# RK3399-AP register map
File version: 1
CPU: CA7 r0p1, little endian, MPU, FPU, I-cache, D-cache, VTOR, 4 interrupt priority bits, 0 interrupts
Registers are 32-bit, read-write, reset 0x0 unless marked. A register's access mark holds for its fields unless they carry their own. Offsets are from the block's base; [hi:lo] are bit positions; {n}, {i} and the like mark numbered series; 'fields as' and 'values as' point back to an identical list.

## GRF (part 1 of 4)
Base 0xFF770000
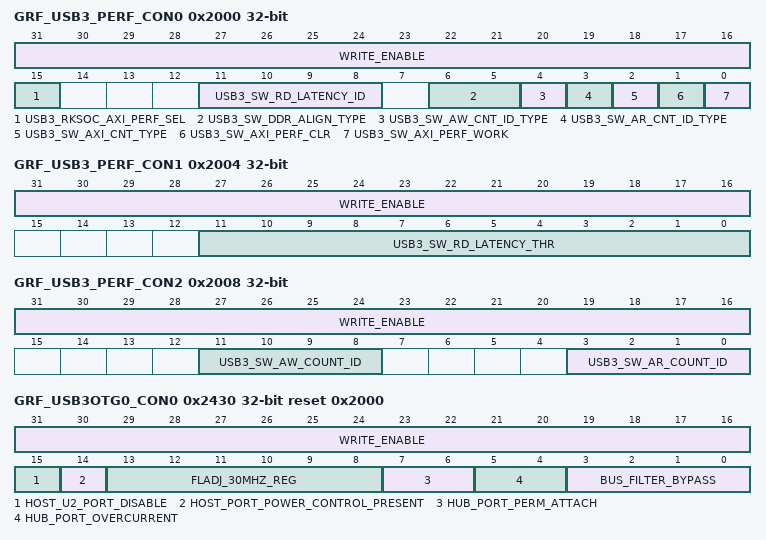
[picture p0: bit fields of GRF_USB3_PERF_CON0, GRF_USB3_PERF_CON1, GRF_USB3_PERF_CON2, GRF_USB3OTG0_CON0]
0x2000 GRF_USB3_PERF_CON0 — usb3 performance monitor control register
  [31:16] WRITE_ENABLE — bit0~15 write enable When bit 16=1, bit 0 can be written by software . When bit 16=0, bit 0 cannot be written by software; When bit 17=1, bit 1 can be written by software . When bit 17=0, bit 1 cannot be written by software; ...... When bit 31=1, bit 15 can be written by software . When bit 31=0, bit 15 cannot be written by software;
  [15] USB3_RKSOC_AXI_PERF_SEL — 0: usb3otg0 1: usb3otg1
  [11:8] USB3_SW_RD_LATENCY_ID — Axi read channel id for latency AXI_PERFormance test
  [6:5] USB3_SW_DDR_ALIGN_TYPE — 0: 16-Byte align 1: 32-Byte align 2: 64-Byte align 3: 128-Byte align
  [4] USB3_SW_AW_CNT_ID_TYPE — axi_perf counter id control 0: count all read channel id 1: count sw_ar_count_id read channel only
  [3] USB3_SW_AR_CNT_ID_TYPE — axi_perf counter id control 0: count all read channel id 1: count sw_ar_count_id read channel only
  [2] USB3_SW_AXI_CNT_TYPE — axi_perf counter type 0: axi transfer test 1: ddr align transfer test
  [1] USB3_SW_AXI_PERF_CLR — Fi axi_perf clear bit 0: disable 1: enable
  [0] USB3_SW_AXI_PERF_WORK — axi_perf enable bit 0: disable 1: enable
0x2004 GRF_USB3_PERF_CON1 — usb3 performance monitor control register
  [31:16] WRITE_ENABLE — bit0~15 write enable When bit 16=1, bit 0 can be written by software . When bit 16=0, bit 0 cannot be written by software; When bit 17=1, bit 1 can be written by software . When bit 17=0, bit 1 cannot be written by software; ...... When bit 31=1, bit 15 can be written by software . When bit 31=0, bit 15 cannot be written by software;
  [11:0] USB3_SW_RD_LATENCY_THR — Axi read channel id for latency AXI_PERFormance test
0x2008 GRF_USB3_PERF_CON2 — usb3 performance monitor control register
  [31:16] WRITE_ENABLE — bit0~15 write enable When bit 16=1, bit 0 can be written by software . When bit 16=0, bit 0 cannot be written by software; When bit 17=1, bit 1 can be written by software . When bit 17=0, bit 1 cannot be written by software; ...... When bit 31=1, bit 15 can be written by software . When bit 31=0, bit 15 cannot be written by software;
  [11:8] USB3_SW_AW_COUNT_ID — When sw_aw_cnt_id_type=1, only count the id designated by sw_aw_count_id
  [3:0] USB3_SW_AR_COUNT_ID — When sw_ar_cnt_id_type=1, only count the id designated by sw_ar_count_id
0x200C GRF_USB3_PERF_RD_MAX_LATENCY_NUM — usb3 performance monitor status register
  [15:0] RD_MAX_LATENCY_R — axi read max latency oaxi read max latency outpututput
0x2010 GRF_USB3_PERF_RD_LATENCY_SAMP_NUM — usb3 performance monitor status register
  [31:0] RD_LATENCY_SAMP_R — AXI read latency total sample number
0x2014 GRF_USB3_PERF_RD_LATENCY_ACC_NUM — usb3 performance monitor status register
  [31:0] RD_LATENCY_ACC_CNT_R — AXI read latency (>sw_rd_latency_thr) total number
0x2018 GRF_USB3_PERF_RD_AXI_TOTAL_BYTE — usb3 performance monitor status register
  [31:0] RD_AXI_TOTAL_BYTE — AXI active total read bytes/ddr align read bytes
0x201C GRF_USB3_PERF_WR_AXI_TOTAL_BYTE — usb3 performance monitor status register
  [31:0] WR_AXI_TOTAL_BYTE — AXI active total write bytes/ddr align write bytes
0x2020 GRF_USB3_PERF_WORKING_CNT — usb3 performance monitor status register
  [31:0] WORKING_CNT_R — working counter
0x2430 GRF_USB3OTG0_CON0 reset 0x2000 — USB3 OTG0 GRF Register0
  [31:16] WRITE_ENABLE — bit0~15 write enable When bit 16=1, bit 0 can be written by software . When bit 16=0, bit 0 cannot be written by software; When bit 17=1, bit 1 can be written by software . When bit 17=0, bit 1 cannot be written by software; ...... When bit 31=1, bit 15 can be written by software . When bit 31=0, bit 15 cannot be written by software;
  [15] HOST_U2_PORT_DISABLE — host_u2_port_disable USB2.0 Port Disable control. 0: Port Enabled 1: Port Disabled When 1, this signal stops reporting connect/disconnect events the port and keeps the port in disabled state.
  [14] HOST_PORT_POWER_CONTROL_PRESENT — host_port_power_control_present This indicates whether the host controller implementation includes port power control. 0: Indicates that the port does not have port power switches. 1: Indicates that the port has port power switches
  [13:8] FLADJ_30MHZ_REG — fladj_30mhz_reg HS Jitter Adjustment. Indicates the correction required to accommodate mac3 clock and utmi clock jitter to measure 125 \'s duration. With fladj_30mhz_reg tied to zero, the high speed 125us micro-frame is counted for 123933ns. You must program the value in terms of high speed bit times in a 30 MHz cycle. The default value that must be driven is 32 (assuming 30 MHz perfect clock).
  [7:6] HUB_PORT_PERM_ATTACH — hub_port_perm_attach Indicates if the device attached to a downstream port is permanently attached or not. 0: Not permanently attached 1: Permanently attached Bit0 is for USB2.0 port and bit1 are for USB 3.0 SS port.
  [5:4] HUB_PORT_OVERCURRENT — hub_port_overcurrent This is the per port Overcurrent indication of the root-hub ports: 0: No Overcurrent 1: Overcurrent Bit0 is for USB 2.0 port and bit1 are for USB 3.0 SS port.
  [3:0] BUS_FILTER_BYPASS — bus_filter_bypass It is expected that this signal is set or reset at power-on reset and is not changed during the normal operation of the core. The function of each bit is: bus_filter_bypass[3]: Bypass the filter for utmiotg_iddig bus_filter_bypass[2]: Bypass the filters for utmisrp_bvalid and utmisrp_sessend bus_filter_bypass[1]: Bypass the filter for pipe3_PowerPresent all U3 ports bus_filter_bypass[0]: Bypass the filter for utmiotg_vbusvalid all U2 ports In non-OTG Host-only mode, internal bus filters are not needed. Values: 1\'b0: Bus filter(s) enabled 1\'b1: Bus filter(s) disabled (bypassed)
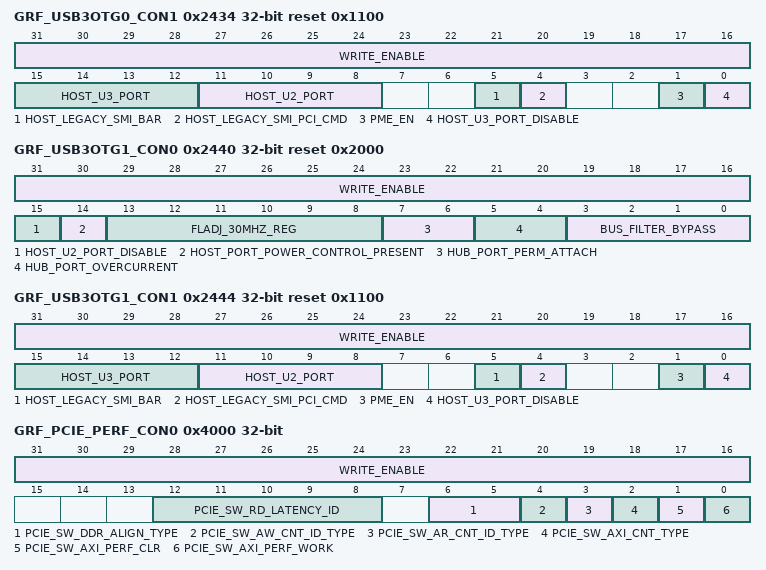
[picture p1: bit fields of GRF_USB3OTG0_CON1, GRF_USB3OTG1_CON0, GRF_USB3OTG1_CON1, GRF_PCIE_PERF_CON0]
0x2434 GRF_USB3OTG0_CON1 reset 0x1100 — USB3 OTG0 GRF Register1
  [31:16] WRITE_ENABLE — bit0~15 write enable When bit 16=1, bit 0 can be written by software . When bit 16=0, bit 0 cannot be written by software; When bit 17=1, bit 1 can be written by software . When bit 17=0, bit 1 cannot be written by software; ...... When bit 31=1, bit 15 can be written by software . When bit 31=0, bit 15 cannot be written by software;
  [15:12] HOST_U3_PORT — host_u3_port xHCI usb3 port number, default as 1.
  [11:8] HOST_U2_PORT — host_u2_port xHCI host USB2 Port number, default as 1.
  [5] HOST_LEGACY_SMI_BAR — host_legacy_smi_bar Use this register to support SMI on BAR defined in xHCI spec. SW must set this register, then clear this register to indicate Base Address Register written
  [4] HOST_LEGACY_SMI_PCI_CMD — host_legacy_smi_pci_cmd Use this register to support SMI on PCI Command defined in xHCI spec. SW must set this register, then clear this register to indicate PCI command register written.
  [1] PME_EN — pme_en Enable signal for the pme_generation. Enable the core to assert pme_generation.
  [0] HOST_U3_PORT_DISABLE — host_u3_port_disable USB 3.0 SS Port Disable control. 0: Port Enabled 1: Port Disabled
0x2440 GRF_USB3OTG1_CON0 reset 0x2000 — USB3 OTG1 GRF Register0
  fields as GRF_USB3OTG0_CON0
0x2444 GRF_USB3OTG1_CON1 reset 0x1100 — USB3 OTG1 GRF Register1
  [31:16] WRITE_ENABLE — bit0~15 write enable When bit 16=1, bit 0 can be written by software . When bit 16=0, bit 0 cannot be written by software; When bit 17=1, bit 1 can be written by software . When bit 17=0, bit 1 cannot be written by software; ...... When bit 31=1, bit 15 can be written by software . When bit 31=0, bit 15 cannot be written by software;
  [15:12] HOST_U3_PORT — host_u3_port xHCI usb3 port number, default as 1.
  [11:8] HOST_U2_PORT — host_u2_port xHCI host USB2 port number, default as 1.
  [5] HOST_LEGACY_SMI_BAR — host_legacy_smi_bar Use this register to support SMI on BAR defined in xHCI spec. SW must set this register, then clear this register to indicate Base Address Register written
  [4] HOST_LEGACY_SMI_PCI_CMD — host_legacy_smi_pci_cmd Use this register to support SMI on PCI Command defined in xHCI spec. SW must set this register, then clear this register to indicate PCI command register written.
  [1] PME_EN — pme_en Enable signal for the pme_generation. Enable the core to assert pme_generation.
  [0] HOST_U3_PORT_DISABLE — host_u3_port_disable USB 3.0 SS Port Disable control. 0: Port Enabled 1: Port Disabled
0x2450 GRF_USB3OTG0_STATUS_LAT0 — USB3 OTG0 status register
  [31:0] USBCPHY0_OTG_UTMI_IDDIG — status of usbcphy0_otg_utmi_iddig[31:0]
0x2454 GRF_USB3OTG0_STATUS_LAT1 — USB3 OTG1 status register
  [31:0] USBCPHY0_OTG_UTMI_IDDIG — status of usbcphy0_otg_utmi_iddig[63:32]
0x2458 GRF_USB3OTG0_STATUS_CB — USB3 OTG0 status register
  [11:0] USB3OTG0_HOST_CURRENT_BELT — status of usb3otg0_host_current_belt
0x2460 GRF_USB3OTG1_STATUS_LAT0 — USB3 OTG1 status register
  [31:0] USBCPHY1_OTG_UTMI_IDDIG — status of usbcphy1_otg_utmi_iddig[31:0]
0x2464 GRF_USB3OTG1_STATUS_LAT1 — USB3 OTG1 status register
  [31:0] USBCPHY1_OTG_UTMI_IDDIG — status of usbcphy1_otg_utmi_iddig[63:32]
0x2468 GRF_USB3OTG1_STATUS_CB — USB3 OTG1 status register
  [11:0] USB3OTG1_HOST_CURRENT_BELT — status of usb3otg1_host_current_belt
0x4000 GRF_PCIE_PERF_CON0 — pcie performance monitor control register
  [31:16] WRITE_ENABLE — bit0~15 write enable When bit 16=1, bit 0 can be written by software . When bit 16=0, bit 0 cannot be written by software; When bit 17=1, bit 1 can be written by software . When bit 17=0, bit 1 cannot be written by software; ...... When bit 31=1, bit 15 can be written by software . When bit 31=0, bit 15 cannot be written by software;
  [12:8] PCIE_SW_RD_LATENCY_ID — Axi read channel id for latency AXI_PERFormance test
  [6:5] PCIE_SW_DDR_ALIGN_TYPE — 0: 16-Byte align 1: 32-Byte align 2: 64-Byte align 3: 128-Byte align
  [4] PCIE_SW_AW_CNT_ID_TYPE — 0: count all write channels 1: count sw_aw_count_id write channel only
  [3] PCIE_SW_AR_CNT_ID_TYPE — axi_perf counter id control 0: count all read channel id 1: count sw_ar_count_id read channel only
  [2] PCIE_SW_AXI_CNT_TYPE — axi_perf counter type 0: axi transfer test 1: ddr align transfer test
  [1] PCIE_SW_AXI_PERF_CLR — axi_perf clear bit 0: disable 1: enable
  [0] PCIE_SW_AXI_PERF_WORK — axi_perf enable bit 0: disable 1: enable
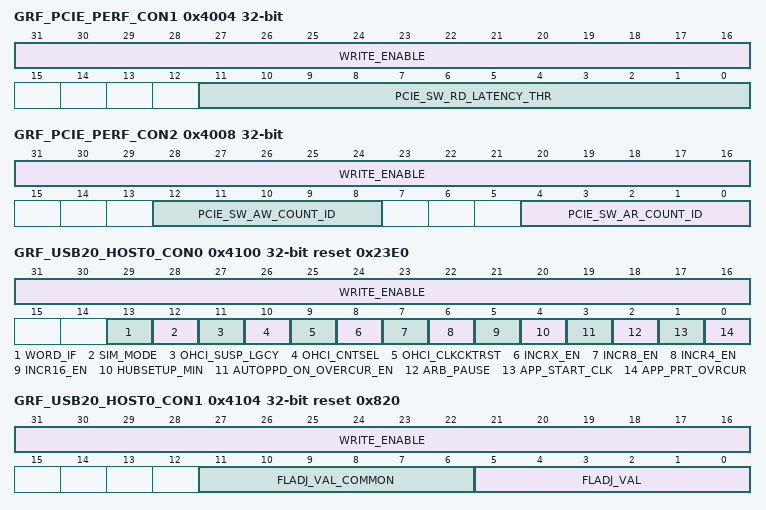
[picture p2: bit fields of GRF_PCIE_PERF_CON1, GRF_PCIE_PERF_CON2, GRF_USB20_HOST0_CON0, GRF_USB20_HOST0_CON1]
0x4004 GRF_PCIE_PERF_CON1 — pcie performance monitor control register
  [31:16] WRITE_ENABLE — bit0~15 write enable When bit 16=1, bit 0 can be written by software . When bit 16=0, bit 0 cannot be written by software; When bit 17=1, bit 1 can be written by software . When bit 17=0, bit 1 cannot be written by software; ...... When bit 31=1, bit 15 can be written by software . When bit 31=0, bit 15 cannot be written by software;
  [11:0] PCIE_SW_RD_LATENCY_THR — Axi read channel id for latency AXI_PERFormance test
0x4008 GRF_PCIE_PERF_CON2 — pcie performance monitor control register
  [31:16] WRITE_ENABLE — bit0~15 write enable When bit 16=1, bit 0 can be written by software . When bit 16=0, bit 0 cannot be written by software; When bit 17=1, bit 1 can be written by software . When bit 17=0, bit 1 cannot be written by software; ...... When bit 31=1, bit 15 can be written by software . When bit 31=0, bit 15 cannot be written by software;
  [12:8] PCIE_SW_AW_COUNT_ID — When sw_aw_cnt_id_type=1, only count the id designated by sw_aw_count_id
  [4:0] PCIE_SW_AR_COUNT_ID — When sw_ar_cnt_id_type=1, only count the id designated by sw_ar_count_id
0x400C GRF_PCIE_PERF_RD_MAX_LATENCY_NUM — pcieperformance monitor status register
  [12:0] RD_MAX_LATENCY_R — axi read max latency output
0x4010 GRF_PCIE_PERF_RD_LATENCY_SAMP_NUM — pcie performance monitor status register
  [26:0] RD_LATENCY_SAMP_R — AXI read latency total sample number
0x4014 GRF_PCIE_PERF_RD_LATENCY_ACC_NUM — pcie performance monitor status register
  fields as GRF_USB3_PERF_RD_LATENCY_ACC_NUM
0x4018 GRF_PCIE_PERF_RD_AXI_TOTAL_BYTE — pcie performance monitor status register
  fields as GRF_USB3_PERF_RD_AXI_TOTAL_BYTE
0x401C GRF_PCIE_PERF_WR_AXI_TOTAL_BYTE — pcie performance monitor status register
  fields as GRF_USB3_PERF_WR_AXI_TOTAL_BYTE
0x4020 GRF_PCIE_PERF_WORKING_CNT — pcie performance monitor status register
  [31:0] WORKING_CNT_R — working counter
0x4100 GRF_USB20_HOST0_CON0 reset 0x23E0 — USB20 Host0 GRF register0
  [31:16] WRITE_ENABLE — bit0~15 write enable When bit 16=1, bit 0 can be written by software . When bit 16=0, bit 0 cannot be written by software; When bit 17=1, bit 1 can be written by software . When bit 17=0, bit 1 cannot be written by software; ...... When bit 31=1, bit 15 can be written by software . When bit 31=0, bit 15 cannot be written by software;
  [13] WORD_IF — word_if 1: select 16bit utmi interface 0: select 8bit utmi interface Note: usb2phy only support 16bit interface.
  [12] SIM_MODE — sim_mode Simulation only.
  [11] OHCI_SUSP_LGCY
  [10] OHCI_CNTSEL
  [9] OHCI_CLKCKTRST
  [8] INCRX_EN — incrx_en Forces AHB master to start INCR4/8/16 busts only on burst boundaries. AHB requires that double word width burst be addressed-aligned only to the double-word boundary. 1\'b1: Start INCRX burst only on burst x-aligned addresses 1\'b0: Normal AHB operation; start bursts on any double word boundary Note: When this function is enabled, the burst are started only when the lowest bits of haddr are: INCR4: haddr[3:0] == 4\'b0000 INCR8: haddr[4:0] == 5\'b00000 INCR16: haddr[5:0] == 6\'b000000
  [7] INCR8_EN — incr8_en 1: enable AHB INCR8 burst 0: disable AHB INCR8 burst
  [6] INCR4_EN — incr4_en 1: enable AHB INCR4 burst 0: disable AHB INCR4 burst
  [5] INCR16_EN — incr16_en 1: enable AHB INCR16 burst 0: disable AHB INCR16 burst
  [4] HUBSETUP_MIN
  [3] AUTOPPD_ON_OVERCUR_EN
  [2] ARB_PAUSE
  [1] APP_START_CLK
  [0] APP_PRT_OVRCUR
0x4104 GRF_USB20_HOST0_CON1 reset 0x820 — USB20 Host0 GRF register1
  [31:16] WRITE_ENABLE — bit0~15 write enable When bit 16=1, bit 0 can be written by software . When bit 16=0, bit 0 cannot be written by software; When bit 17=1, bit 1 can be written by software . When bit 17=0, bit 1 cannot be written by software; ...... When bit 31=1, bit 15 can be written by software . When bit 31=0, bit 15 cannot be written by software;
  [11:6] FLADJ_VAL_COMMON — fladj_val_common Must set this register to 0x20.
  [5:0] FLADJ_VAL — fladj_val Must set this register to 0x20.
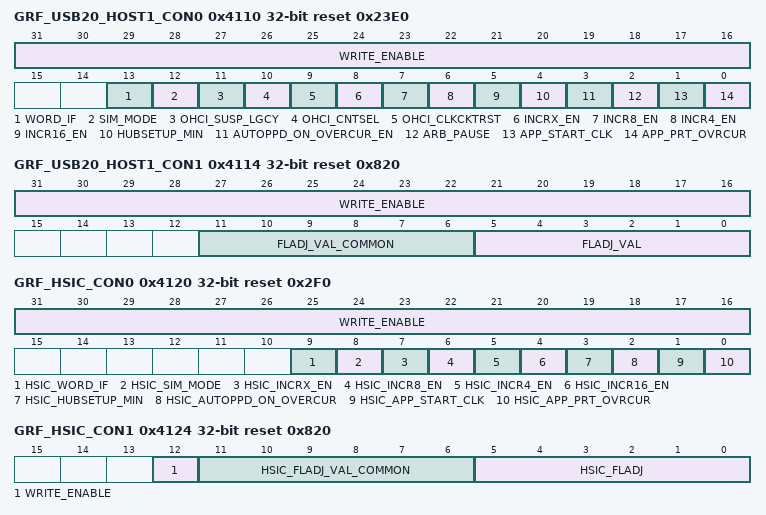
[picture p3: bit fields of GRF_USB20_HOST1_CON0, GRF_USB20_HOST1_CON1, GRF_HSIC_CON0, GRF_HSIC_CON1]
0x4110 GRF_USB20_HOST1_CON0 reset 0x23E0 — USB20 Host1 GRF register0
  fields as GRF_USB20_HOST0_CON0
0x4114 GRF_USB20_HOST1_CON1 reset 0x820 — USB20 Host1 GRF register1
  fields as GRF_USB20_HOST0_CON1
0x4120 GRF_HSIC_CON0 reset 0x2F0 — HSIC controller GRF register 0
  [31:16] WRITE_ENABLE — bit0~15 write enable When bit 16=1, bit 0 can be written by software . When bit 16=0, bit 0 cannot be written by software; When bit 17=1, bit 1 can be written by software . When bit 17=0, bit 1 cannot be written by software; ...... When bit 31=1, bit 15 can be written by software . When bit 31=0, bit 15 cannot be written by software;
  [9] HSIC_WORD_IF — word_if 1: select 16bit utmi interface 0: select 8bit utmi interface Note: HSICPHY only support 16bit utmi interface.
  [8] HSIC_SIM_MODE — sim_mode Simulation only.
  [7] HSIC_INCRX_EN — Burst Alignment Enable Forces AHB master to start INCR4/8/16 busts only on burst boundaries. AHB requires that double word width burst be addressed-aligned only to the double-word boundary. 1\'b1: Start INCRX burst only on burst x-aligned addresses 1\'b0: Normal AHB operation; start bursts on any double word boundary Note: When this function is enabled, the burst are started only when the lowest bits of haddr are: INCR4: haddr[3:0] == 4\'b0000 INCR8: haddr[4:0] == 5\'b00000 INCR16: haddr[5:0] == 6\'b000000
  [6] HSIC_INCR8_EN — incr8_en 1: enable AHB INCR8 burst 0: disable AHB INCR8 burst
  [5] HSIC_INCR4_EN — incr4_en 1: enable AHB INCR4 burst 0: disable AHB INCR4 burst
  [4] HSIC_INCR16_EN — incr16_en 1: enable AHB INCR16 burst 0: disable AHB INCR16 burst
  [3] HSIC_HUBSETUP_MIN — hubsetup_min
  [2] HSIC_AUTOPPD_ON_OVERCUR — autoppd_on_overcur
  [1] HSIC_APP_START_CLK — app_start_clk
  [0] HSIC_APP_PRT_OVRCUR — app_prt_ovrcur
0x4124 GRF_HSIC_CON1 reset 0x820 — HSIC controller GRF register1
  [12] WRITE_ENABLE — bit0~15 write enable When bit 16=1, bit 0 can be written by software . When bit 16=0, bit 0 cannot be written by software; When bit 17=1, bit 1 can be written by software . When bit 17=0, bit 1 cannot be written by software; ...... When bit 31=1, bit 15 can be written by software . When bit 31=0, bit 15 cannot be written by software;
  [11:6] HSIC_FLADJ_VAL_COMMON — fladj_val_common Must set this register to 0x20
  [5:0] HSIC_FLADJ — fladj Must set this register to 0x20.
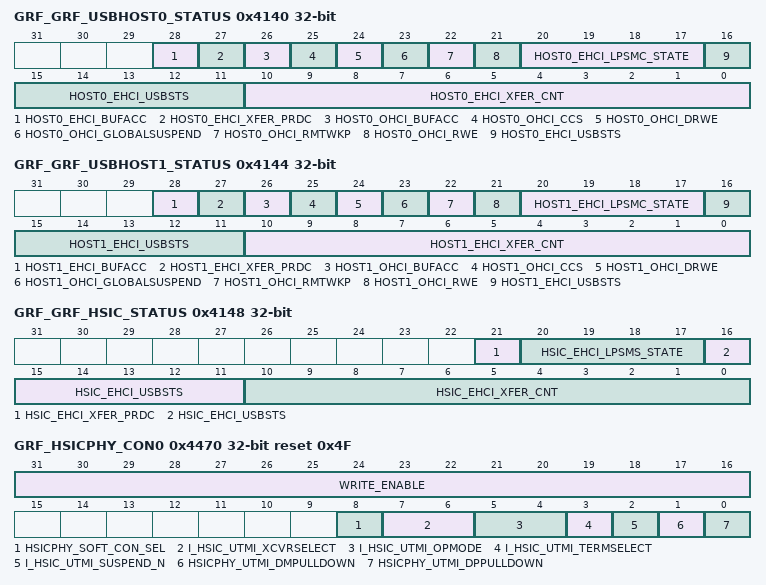
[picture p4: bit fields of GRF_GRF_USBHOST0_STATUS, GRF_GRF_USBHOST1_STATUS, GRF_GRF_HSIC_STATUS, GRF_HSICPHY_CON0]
0x4140 GRF_GRF_USBHOST0_STATUS — usb host0 controller status register
  [28] HOST0_EHCI_BUFACC, [27] HOST0_EHCI_XFER_PRDC, [26] HOST0_OHCI_BUFACC, [25] HOST0_OHCI_CCS, [24] HOST0_OHCI_DRWE, [23] HOST0_OHCI_GLOBALSUSPEND, [22] HOST0_OHCI_RMTWKP, [21] HOST0_OHCI_RWE, [20:17] HOST0_EHCI_LPSMC_STATE, [16:11] HOST0_EHCI_USBSTS, [10:0] HOST0_EHCI_XFER_CNT
0x4144 GRF_GRF_USBHOST1_STATUS — usb host1 controller status register
  [28] HOST1_EHCI_BUFACC, [27] HOST1_EHCI_XFER_PRDC, [26] HOST1_OHCI_BUFACC, [25] HOST1_OHCI_CCS, [24] HOST1_OHCI_DRWE, [23] HOST1_OHCI_GLOBALSUSPEND, [22] HOST1_OHCI_RMTWKP, [21] HOST1_OHCI_RWE, [20:17] HOST1_EHCI_LPSMC_STATE, [16:11] HOST1_EHCI_USBSTS, [10:0] HOST1_EHCI_XFER_CNT
0x4148 GRF_GRF_HSIC_STATUS — hsic controller status register
  [21] HSIC_EHCI_XFER_PRDC, [20:17] HSIC_EHCI_LPSMS_STATE, [16:11] HSIC_EHCI_USBSTS, [10:0] HSIC_EHCI_XFER_CNT
0x4470 GRF_HSICPHY_CON0 reset 0x4F — HSICPHY GRF control register
  [31:16] WRITE_ENABLE — bit0~15 write enable When bit 16=1, bit 0 can be written by software . When bit 16=0, bit 0 cannot be written by software; When bit 17=1, bit 1 can be written by software . When bit 17=0, bit 1 cannot be written by software; ...... When bit 31=1, bit 15 can be written by software . When bit 31=0, bit 15 cannot be written by software;
  [8] HSICPHY_SOFT_CON_SEL — soft_con_sel 1: soft control select utmi signals from GRF to HSIC PHY 0: soft control select utmi signals from HSIC controller to HSIC PHY
  [7:6] I_HSIC_UTMI_XCVRSELECT — utmi_xcvrselect select the value of this register to xcvrselect port of HSIC PHY when soft_con_sel=1.
  [5:4] I_HSIC_UTMI_OPMODE — utmi_opmode select the value of this register to opmode port of HSIC PHY when soft_con_sel=1
  [3] I_HSIC_UTMI_TERMSELECT — utmi_termselect select the value of this register to termselect port of HSIC PHY when soft_con_sel=1
  [2] I_HSIC_UTMI_SUSPEND_N — utmi_suspend_n select the value of this register to ususpend_n port of HSIC PHY when soft_con_sel=1
  [1] HSICPHY_UTMI_DMPULLDOWN — utmi_dmpulldown 1:DM pull down resistor enable 0:DM pull down resistor disable
  [0] HSICPHY_UTMI_DPPULLDOWN — utmi_dppulldown 1:DP pull down resistor enable 0:DP pull down resistor disable write_enable bit0~15 write enable When bit 16=1, bit 0 can be written by software . When bit 16=0, bit 0 cannot be written by software; When bit 17=1, bit 1 can be written by software . When bit 17=0, bit 1 cannot be written by software; ...... When bit 31=1, bit 15 can be written by software . When bit 31=0, bit 15 cannot be written by software; usbphy_ctrl0 usbphy_ctrl0 Bit0~15 of usbphy_ctrl register write_enable bit0~15 write enable When bit 16=1, bit 0 can be written by software . When bit 16=0, bit 0 cannot be written by software; When bit 17=1, bit 1 can be written by software . When bit 17=0, bit 1 cannot be written by software; ...... When bit 31=1, bit 15 can be written by software . When bit 31=0, bit 15 cannot be written by software; usbphy_ctrl1 usbphy_ctrl1 Bit16~31 of usbphy_ctrl register write_enable bit0~15 write enable When bit 16=1, bit 0 can be written by software . When bit 16=0, bit 0 cannot be written by software; When bit 17=1, bit 1 can be written by software . When bit 17=0, bit 1 cannot be written by software; ...... When bit 31=1, bit 15 can be written by software . When bit 31=0, bit 15 cannot be written by software; usbphy_ctrl2 usbphy_ctrl2 Bit32~47 of usbphy_ctrl register write_enable bit0~15 write enable When bit 16=1, bit 0 can be written by software . When bit 16=0, bit 0 cannot be written by software; When bit 17=1, bit 1 can be written by software . When bit 17=0, bit 1 cannot be written by software; ...... When bit 31=1, bit 15 can be written by software . When bit 31=0, bit 15 cannot be written by software; usbphy_ctrl3 usbphy_ctrl3 Bit48~63 of usbphy_ctrl register write_enable bit0~15 write enable When bit 16=1, bit 0 can be written by software . When bit 16=0, bit 0 cannot be written by software; When bit 17=1, bit 1 can be written by software . When bit 17=0, bit 1 cannot be written by software; ...... When bit 31=1, bit 15 can be written by software . When bit 31=0, bit 15 cannot be written by software; usbphy_ctrl4 usbphy_ctrl4 Bit64~79 of usbphy_ctrl register write_enable bit0~15 write enable When bit 16=1, bit 0 can be written by software . When bit 16=0, bit 0 cannot be written by software; When bit 17=1, bit 1 can be written by software . When bit 17=0, bit 1 cannot be written by software; ...... When bit 31=1, bit 15 can be written by software . When bit 31=0, bit 15 cannot be written by software; usbphy_ctrl5 usbphy_ctrl5 Bit80~95 of usbphy_ctrl register write_enable bit0~15 write enable When bit 16=1, bit 0 can be written by software . When bit 16=0, bit 0 cannot be written by software; When bit 17=1, bit 1 can be written by software . When bit 17=0, bit 1 cannot be written by software; ...... When bit 31=1, bit 15 can be written by software . When bit 31=0, bit 15 cannot be written by software; usbphy_ctrl6 usbphy_ctrl6 Bit96~111 of usbphy_ctrl register write_enable bit0~15 write enable When bit 16=1, bit 0 can be written by software . When bit 16=0, bit 0 cannot be written by software; When bit 17=1, bit 1 can be written by software . When bit 17=0, bit 1 cannot be written by software; ...... When bit 31=1, bit 15 can be written by software . When bit 31=0, bit 15 cannot be written by software; usbphy_ctrl7 usbphy_ctrl7 Bit112~127 of usbphy_ctrl register write_enable bit0~15 write enable When bit 16=1, bit 0 can be written by software . When bit 16=0, bit 0 cannot be written by software; When bit 17=1, bit 1 can be written by software . When bit 17=0, bit 1 cannot be written by software; ...... When bit 31=1, bit 15 can be written by software . When bit 31=0, bit 15 cannot be written by software; usbphy_ctrl8 usbphy_ctrl8 Bit128~143 of usbphy_ctrl register write_enable bit0~15 write enable When bit 16=1, bit 0 can be written by software . When bit 16=0, bit 0 cannot be written by software; When bit 17=1, bit 1 can be written by software . When bit 17=0, bit 1 cannot be written by software; ...... When bit 31=1, bit 15 can be written by software . When bit 31=0, bit 15 cannot be written by software; usbphy_ctrl9 usbphy_ctrl9 Bit144~159 of usbphy_ctrl register write_enable bit0~15 write enable When bit 16=1, bit 0 can be written by software . When bit 16=0, bit 0 cannot be written by software; When bit 17=1, bit 1 can be written by software . When bit 17=0, bit 1 cannot be written by software; ...... When bit 31=1, bit 15 can be written by software . When bit 31=0, bit 15 cannot be written by software; usbphy_ctrl10 usbphy_ctrl10 Bit160~175 of usbphy_ctrl register write_enable bit0~15 write enable When bit 16=1, bit 0 can be written by software . When bit 16=0, bit 0 cannot be written by software; When bit 17=1, bit 1 can be written by software . When bit 17=0, bit 1 cannot be written by software; ...... When bit 31=1, bit 15 can be written by software . When bit 31=0, bit 15 cannot be written by software; usbphy_ctrl11 usbphy_ctrl11 Bit176~191 of usbphy_ctrl register write_enable bit0~15 write enable When bit 16=1, bit 0 can be written by software . When bit 16=0, bit 0 cannot be written by software; When bit 17=1, bit 1 can be written by software . When bit 17=0, bit 1 cannot be written by software; ...... When bit 31=1, bit 15 can be written by software . When bit 31=0, bit 15 cannot be written by software; usbphy_ctrl12 usbphy_ctrl12 Bit192~207 of usbphy_ctrl register write_enable bit0~15 write enable When bit 16=1, bit 0 can be written by software . When bit 16=0, bit 0 cannot be written by software; When bit 17=1, bit 1 can be written by software . When bit 17=0, bit 1 cannot be written by software; ...... When bit 31=1, bit 15 can be written by software . When bit 31=0, bit 15 cannot be written by software; usbphy_ctrl13 usbphy_ctrl13 Bit208~223 of usbphy_ctrl register write_enable bit0~15 write enable When bit 16=1, bit 0 can be written by software . When bit 16=0, bit 0 cannot be written by software; When bit 17=1, bit 1 can be written by software . When bit 17=0, bit 1 cannot be written by software; ...... When bit 31=1, bit 15 can be written by software . When bit 31=0, bit 15 cannot be written by software; usbphy_ctrl14 usbphy_ctrl14 Bit224~239 of usbphy_ctrl register write_enable bit0~15 write enable When bit 16=1, bit 0 can be written by software . When bit 16=0, bit 0 cannot be written by software; When bit 17=1, bit 1 can be written by software . When bit 17=0, bit 1 cannot be written by software; ...... When bit 31=1, bit 15 can be written by software . When bit 31=0, bit 15 cannot be written by software; usbphy_ctrl15 usbphy_ctrl15 Bit240~255 of usbphy_ctrl register write_enable bit0~15 write enable When bit 16=1, bit 0 can be written by software . When bit 16=0, bit 0 cannot be written by software; When bit 17=1, bit 1 can be written by software . When bit 17=0, bit 1 cannot be written by software; ...... When bit 31=1, bit 15 can be written by software . When bit 31=0, bit 15 cannot be written by software; usbphy_ctrl16 usbphy_ctrl16 Bit256~271 of usbphy_ctrl register write_enable bit0~15 write enable When bit 16=1, bit 0 can be written by software . When bit 16=0, bit 0 cannot be written by software; When bit 17=1, bit 1 can be written by software . When bit 17=0, bit 1 cannot be written by software; ...... When bit 31=1, bit 15 can be written by software . When bit 31=0, bit 15 cannot be written by software; usbphy_ctrl17 usbphy_ctrl17 Bit272~287 of usbphy_ctrl register write_enable bit0~15 write enable When bit 16=1, bit 0 can be written by software . When bit 16=0, bit 0 cannot be written by software; When bit 17=1, bit 1 can be written by software . When bit 17=0, bit 1 cannot be written by software; ...... When bit 31=1, bit 15 can be written by software . When bit 31=0, bit 15 cannot be written by software; usbphy_ctrl18 usbphy_ctrl18 Bit288~303 of usbphy_ctrl register write_enable bit0~15 write enable When bit 16=1, bit 0 can be written by software . When bit 16=0, bit 0 cannot be written by software; When bit 17=1, bit 1 can be written by software . When bit 17=0, bit 1 cannot be written by software; ...... When bit 31=1, bit 15 can be written by software . When bit 31=0, bit 15 cannot be written by software; usbphy_ctrl19 usbphy_ctrl19 Bit304~319 of usbphy_ctrl register write_enable bit0~15 write enable When bit 16=1, bit 0 can be written by software . When bit 16=0, bit 0 cannot be written by software; When bit 17=1, bit 1 can be written by software . When bit 17=0, bit 1 cannot be written by software; ...... When bit 31=1, bit 15 can be written by software . When bit 31=0, bit 15 cannot be written by software; usbphy_ctrl20 usbphy_ctrl20 Bit320~335 of usbphy_ctrl register write_enable bit0~15 write enable When bit 16=1, bit 0 can be written by software . When bit 16=0, bit 0 cannot be written by software; When bit 17=1, bit 1 can be written by software . When bit 17=0, bit 1 cannot be written by software; ...... When bit 31=1, bit 15 can be written by software . When bit 31=0, bit 15 cannot be written by software; usbphy_ctrl21 usbphy_ctrl21 Bit336~351 of usbphy_ctrl register write_enable bit0~15 write enable When bit 16=1, bit 0 can be written by software . When bit 16=0, bit 0 cannot be written by software; When bit 17=1, bit 1 can be written by software . When bit 17=0, bit 1 cannot be written by software; ...... When bit 31=1, bit 15 can be written by software . When bit 31=0, bit 15 cannot be written by software; usbphy_ctrl22 usbphy_ctrl22 Bit352~367 of usbphy_ctrl register write_enable bit0~15 write enable When bit 16=1, bit 0 can be written by software . When bit 16=0, bit 0 cannot be written by software; When bit 17=1, bit 1 can be written by software . When bit 17=0, bit 1 cannot be written by software; ...... When bit 31=1, bit 15 can be written by software . When bit 31=0, bit 15 cannot be written by software; usbphy_ctrl23 usbphy_ctrl23 Bit368~383 of usbphy_ctrl register write_enable bit0~15 write enable When bit 16=1, bit 0 can be written by software . When bit 16=0, bit 0 cannot be written by software; When bit 17=1, bit 1 can be written by software . When bit 17=0, bit 1 cannot be written by software; ...... When bit 31=1, bit 15 can be written by software . When bit 31=0, bit 15 cannot be written by software; usbphy_ctrl24 usbphy_ctrl24 Bit384~399 of usbphy_ctrl register write_enable bit0~15 write enable When bit 16=1, bit 0 can be written by software . When bit 16=0, bit 0 cannot be written by software; When bit 17=1, bit 1 can be written by software . When bit 17=0, bit 1 cannot be written by software; ...... When bit 31=1, bit 15 can be written by software . When bit 31=0, bit 15 cannot be written by software; usbphy_ctrl25 usbphy_ctrl25 Bit400~415 of usbphy_ctrl register write_enable bit0~15 write enable When bit 16=1, bit 0 can be written by software . When bit 16=0, bit 0 cannot be written by software; When bit 17=1, bit 1 can be written by software . When bit 17=0, bit 1 cannot be written by software; ...... When bit 31=1, bit 15 can be written by software . When bit 31=0, bit 15 cannot be written by software; usbphy_ctrl0 usbphy_ctrl0 Bit0~15 of usbphy_ctrl register write_enable bit0~15 write enable When bit 16=1, bit 0 can be written by software . When bit 16=0, bit 0 cannot be written by software; When bit 17=1, bit 1 can be written by software . When bit 17=0, bit 1 cannot be written by software; ...... When bit 31=1, bit 15 can be written by software . When bit 31=0, bit 15 cannot be written by software; usbphy_ctrl1 usbphy_ctrl1 Bit16~31 of usbphy_ctrl register write_enable bit0~15 write enable When bit 16=1, bit 0 can be written by software . When bit 16=0, bit 0 cannot be written by software; When bit 17=1, bit 1 can be written by software . When bit 17=0, bit 1 cannot be written by software; ...... When bit 31=1, bit 15 can be written by software . When bit 31=0, bit 15 cannot be written by software; usbphy_ctrl2 usbphy_ctrl2 Bit32~47 of usbphy_ctrl register write_enable bit0~15 write enable When bit 16=1, bit 0 can be written by software . When bit 16=0, bit 0 cannot be written by software; When bit 17=1, bit 1 can be written by software . When bit 17=0, bit 1 cannot be written by software; ...... When bit 31=1, bit 15 can be written by software . When bit 31=0, bit 15 cannot be written by software; usbphy_ctrl3 usbphy_ctrl3 Bit48~63 of usbphy_ctrl register write_enable bit0~15 write enable When bit 16=1, bit 0 can be written by software . When bit 16=0, bit 0 cannot be written by software; When bit 17=1, bit 1 can be written by software . When bit 17=0, bit 1 cannot be written by software; ...... When bit 31=1, bit 15 can be written by software . When bit 31=0, bit 15 cannot be written by software; usbphy_ctrl4 usbphy_ctrl4 Bit64~79 of usbphy_ctrl register write_enable bit0~15 write enable When bit 16=1, bit 0 can be written by software . When bit 16=0, bit 0 cannot be written by software; When bit 17=1, bit 1 can be written by software . When bit 17=0, bit 1 cannot be written by software; ...... When bit 31=1, bit 15 can be written by software . When bit 31=0, bit 15 cannot be written by software; usbphy_ctrl5 usbphy_ctrl5 Bit80~95 of usbphy_ctrl register write_enable bit0~15 write enable When bit 16=1, bit 0 can be written by software . When bit 16=0, bit 0 cannot be written by software; When bit 17=1, bit 1 can be written by software . When bit 17=0, bit 1 cannot be written by software; ...... When bit 31=1, bit 15 can be written by software . When bit 31=0, bit 15 cannot be written by software; usbphy_ctrl6 usbphy_ctrl6 Bit96~111 of usbphy_ctrl register write_enable bit0~15 write enable When bit 16=1, bit 0 can be written by software . When bit 16=0, bit 0 cannot be written by software; When bit 17=1, bit 1 can be written by software . When bit 17=0, bit 1 cannot be written by software; ...... When bit 31=1, bit 15 can be written by software . When bit 31=0, bit 15 cannot be written by software; usbphy_ctrl7 usbphy_ctrl7 Bit112~127 of usbphy_ctrl register write_enable bit0~15 write enable When bit 16=1, bit 0 can be written by software . When bit 16=0, bit 0 cannot be written by software; When bit 17=1, bit 1 can be written by software . When bit 17=0, bit 1 cannot be written by software; ...... When bit 31=1, bit 15 can be written by software . When bit 31=0, bit 15 cannot be written by software; usbphy_ctrl8 usbphy_ctrl8 Bit128~143 of usbphy_ctrl register write_enable bit0~15 write enable When bit 16=1, bit 0 can be written by software . When bit 16=0, bit 0 cannot be written by software; When bit 17=1, bit 1 can be written by software . When bit 17=0, bit 1 cannot be written by software; ...... When bit 31=1, bit 15 can be written by software . When bit 31=0, bit 15 cannot be written by software; usbphy_ctrl9 usbphy_ctrl9 Bit144~159 of usbphy_ctrl register write_enable bit0~15 write enable When bit 16=1, bit 0 can be written by software . When bit 16=0, bit 0 cannot be written by software; When bit 17=1, bit 1 can be written by software . When bit 17=0, bit 1 cannot be written by software; ...... When bit 31=1, bit 15 can be written by software . When bit 31=0, bit 15 cannot be written by software; usbphy_ctrl10 usbphy_ctrl10 Bit160~175 of usbphy_ctrl register write_enable bit0~15 write enable When bit 16=1, bit 0 can be written by software . When bit 16=0, bit 0 cannot be written by software; When bit 17=1, bit 1 can be written by software . When bit 17=0, bit 1 cannot be written by software; ...... When bit 31=1, bit 15 can be written by software . When bit 31=0, bit 15 cannot be written by software; usbphy_ctrl11 usbphy_ctrl11 Bit176~191 of usbphy_ctrl register write_enable bit0~15 write enable When bit 16=1, bit 0 can be written by software . When bit 16=0, bit 0 cannot be written by software; When bit 17=1, bit 1 can be written by software . When bit 17=0, bit 1 cannot be written by software; ...... When bit 31=1, bit 15 can be written by software . When bit 31=0, bit 15 cannot be written by software; usbphy_ctrl12 usbphy_ctrl12 Bit192~207 of usbphy_ctrl register write_enable bit0~15 write enable When bit 16=1, bit 0 can be written by software . When bit 16=0, bit 0 cannot be written by software; When bit 17=1, bit 1 can be written by software . When bit 17=0, bit 1 cannot be written by software; ...... When bit 31=1, bit 15 can be written by software . When bit 31=0, bit 15 cannot be written by software; usbphy_ctrl13 usbphy_ctrl13 Bit208~223 of usbphy_ctrl register write_enable bit0~15 write enable When bit 16=1, bit 0 can be written by software . When bit 16=0, bit 0 cannot be written by software; When bit 17=1, bit 1 can be written by software . When bit 17=0, bit 1 cannot be written by software; ...... When bit 31=1, bit 15 can be written by software . When bit 31=0, bit 15 cannot be written by software; usbphy_ctrl14 usbphy_ctrl14 Bit224~239 of usbphy_ctrl register write_enable bit0~15 write enable When bit 16=1, bit 0 can be written by software . When bit 16=0, bit 0 cannot be written by software; When bit 17=1, bit 1 can be written by software . When bit 17=0, bit 1 cannot be written by software; ...... When bit 31=1, bit 15 can be written by software . When bit 31=0, bit 15 cannot be written by software; usbphy_ctrl15 usbphy_ctrl15 Bit240~255 of usbphy_ctrl register write_enable bit0~15 write enable When bit 16=1, bit 0 can be written by software . When bit 16=0, bit 0 cannot be written by software; When bit 17=1, bit 1 can be written by software . When bit 17=0, bit 1 cannot be written by software; ...... When bit 31=1, bit 15 can be written by software . When bit 31=0, bit 15 cannot be written by software; usbphy_ctrl16 usbphy_ctrl16 Bit256~271 of usbphy_ctrl register write_enable bit0~15 write enable When bit 16=1, bit 0 can be written by software . When bit 16=0, bit 0 cannot be written by software; When bit 17=1, bit 1 can be written by software . When bit 17=0, bit 1 cannot be written by software; ...... When bit 31=1, bit 15 can be written by software . When bit 31=0, bit 15 cannot be written by software; usbphy_ctrl17 usbphy_ctrl17 Bit272~287 of usbphy_ctrl register write_enable bit0~15 write enable When bit 16=1, bit 0 can be written by software . When bit 16=0, bit 0 cannot be written by software; When bit 17=1, bit 1 can be written by software . When bit 17=0, bit 1 cannot be written by software; ...... When bit 31=1, bit 15 can be written by software . When bit 31=0, bit 15 cannot be written by software; usbphy_ctrl18 usbphy_ctrl18 Bit288~303 of usbphy_ctrl register write_enable bit0~15 write enable When bit 16=1, bit 0 can be written by software . When bit 16=0, bit 0 cannot be written by software; When bit 17=1, bit 1 can be written by software . When bit 17=0, bit 1 cannot be written by software; ...... When bit 31=1, bit 15 can be written by software . When bit 31=0, bit 15 cannot be written by software; usbphy_ctrl19 usbphy_ctrl19 Bit304~319 of usbphy_ctrl register write_enable bit0~15 write enable When bit 16=1, bit 0 can be written by software . When bit 16=0, bit 0 cannot be written by software; When bit 17=1, bit 1 can be written by software . When bit 17=0, bit 1 cannot be written by software; ...... When bit 31=1, bit 15 can be written by software . When bit 31=0, bit 15 cannot be written by software; usbphy_ctrl20 usbphy_ctrl20 Bit320~335 of usbphy_ctrl register write_enable bit0~15 write enable When bit 16=1, bit 0 can be written by software . When bit 16=0, bit 0 cannot be written by software; When bit 17=1, bit 1 can be written by software . When bit 17=0, bit 1 cannot be written by software; ...... When bit 31=1, bit 15 can be written by software . When bit 31=0, bit 15 cannot be written by software; usbphy_ctrl21 usbphy_ctrl21 Bit336~351 of usbphy_ctrl register write_enable bit0~15 write enable When bit 16=1, bit 0 can be written by software . When bit 16=0, bit 0 cannot be written by software; When bit 17=1, bit 1 can be written by software . When bit 17=0, bit 1 cannot be written by software; ...... When bit 31=1, bit 15 can be written by software . When bit 31=0, bit 15 cannot be written by software; usbphy_ctrl22 usbphy_ctrl22 Bit352~367 of usbphy_ctrl register write_enable bit0~15 write enable When bit 16=1, bit 0 can be written by software . When bit 16=0, bit 0 cannot be written by software; When bit 17=1, bit 1 can be written by software . When bit 17=0, bit 1 cannot be written by software; ...... When bit 31=1, bit 15 can be written by software . When bit 31=0, bit 15 cannot be written by software; usbphy_ctrl23 usbphy_ctrl23 Bit368~383 of usbphy_ctrl register write_enable bit0~15 write enable When bit 16=1, bit 0 can be written by software . When bit 16=0, bit 0 cannot be written by software; When bit 17=1, bit 1 can be written by software . When bit 17=0, bit 1 cannot be written by software; ...... When bit 31=1, bit 15 can be written by software . When bit 31=0, bit 15 cannot be written by software; usbphy_ctrl24 usbphy_ctrl24 Bit384~399 of usbphy_ctrl register write_enable bit0~15 write enable When bit 16=1, bit 0 can be written by software . When bit 16=0, bit 0 cannot be written by software; When bit 17=1, bit 1 can be written by software . When bit 17=0, bit 1 cannot be written by software; ...... When bit 31=1, bit 15 can be written by software . When bit 31=0, bit 15 cannot be written by software; usbphy_ctrl25 usbphy_ctrl25 Bit400~415 of usbphy_ctrl register
0x4480 GRF_usbphy0_ctrl0 access not given reset 0x850F — usbphy0_ctrl0
0x4484 GRF_usbphy0_ctrl1 access not given reset 0xE007 — usbphy0_ctrl1
0x4488 GRF_usbphy0_ctrl2 access not given reset 0x82E7 — usbphy0_ctrl2
0x448C GRF_usbphy0_ctrl3 access not given reset 0x2A2 — usbphy0_ctrl3
0x4490 GRF_usbphy0_ctrl4 access not given reset 0x5554 — usbphy0_ctrl4
0x4494 GRF_usbphy0_ctrl5 access not given reset 0x4555 — usbphy0_ctrl5
0x4498 GRF_usbphy0_ctrl6 access not given reset 0x5 — usbphy0_ctrl6
0x449C GRF_usbphy0_ctrl7 access not given reset 0x68C8 — usbphy0_ctrl7
{0x4480+4i} GRF_usbphy0_ctrl{i} access not given (i=8..11) — usbphy0_ctrl{i}
0x44B0 GRF_usbphy0_ctrl12 access not given reset 0xA1 — usbphy0_ctrl12
0x44B4 GRF_usbphy0_ctrl13 access not given reset 0x850F — usbphy0_ctrl13
0x44B8 GRF_usbphy0_ctrl14 access not given reset 0xE007 — usbphy0_ctrl14
0x44BC GRF_usbphy0_ctrl15 access not given reset 0x2E7 — usbphy0_ctrl15
0x44C0 GRF_usbphy0_ctrl16 access not given reset 0x200 — usbphy0_ctrl16
0x44C4 GRF_usbphy0_ctrl17 access not given reset 0x5554 — usbphy0_ctrl17
0x44C8 GRF_usbphy0_ctrl18 access not given reset 0x4555 — usbphy0_ctrl18
0x44CC GRF_usbphy0_ctrl19 access not given reset 0x5 — usbphy0_ctrl19
0x44D0 GRF_usbphy0_ctrl20 access not given reset 0x68C8 — usbphy0_ctrl20
{0x4480+4i} GRF_usbphy0_ctrl{i} access not given (i=21..24) — usbphy0_ctrl{i}
0x44E4 GRF_usbphy0_ctrl25 access not given reset 0x21 — usbphy0_ctrl25
0x4500 GRF_usbphy1_ctrl0 access not given reset 0x850F — usbphy1_ctrl0
0x4504 GRF_usbphy1_ctrl1 access not given reset 0xE007 — usbphy1_ctrl1
0x4508 GRF_usbphy1_ctrl2 access not given reset 0x82E7 — usbphy1_ctrl2
0x450C GRF_usbphy1_ctrl3 access not given reset 0x2A2 — usbphy1_ctrl3
0x4510 GRF_usbphy1_ctrl4 access not given reset 0x5554 — usbphy1_ctrl4
0x4514 GRF_usbphy1_ctrl5 access not given reset 0x4555 — usbphy1_ctrl5
0x4518 GRF_usbphy1_ctrl6 access not given reset 0x5 — usbphy1_ctrl6
0x451C GRF_usbphy1_ctrl7 access not given reset 0x68C8 — usbphy1_ctrl7
{0x4500+4i} GRF_usbphy1_ctrl{i} access not given (i=8..11) — usbphy1_ctrl{i}
0x4530 GRF_usbphy1_ctrl12 access not given reset 0xA1 — usbphy1_ctrl12
0x4534 GRF_usbphy1_ctrl13 access not given reset 0x850F — usbphy1_ctrl13
0x4538 GRF_usbphy1_ctrl14 access not given reset 0xE007 — usbphy1_ctrl14
0x453C GRF_usbphy1_ctrl15 access not given reset 0x2E7 — usbphy1_ctrl15
0x4540 GRF_usbphy1_ctrl16 access not given reset 0x200 — usbphy1_ctrl16
0x4544 GRF_usbphy1_ctrl17 access not given reset 0x5554 — usbphy1_ctrl17
0x4548 GRF_usbphy1_ctrl18 access not given reset 0x4555 — usbphy1_ctrl18
0x454C GRF_usbphy1_ctrl19 access not given reset 0x5 — usbphy1_ctrl19
0x4550 GRF_usbphy1_ctrl20 access not given reset 0x68C8 — usbphy1_ctrl20
{0x4500+4i} GRF_usbphy1_ctrl{i} access not given (i=21..24) — usbphy1_ctrl{i}
0x4564 GRF_usbphy1_ctrl25 access not given reset 0x21 — usbphy1_ctrl25
